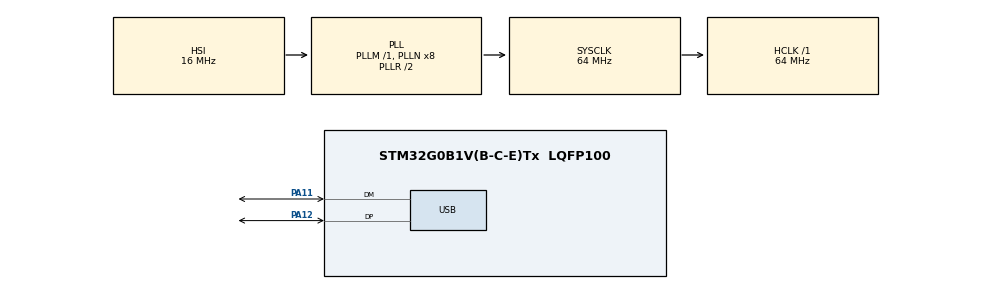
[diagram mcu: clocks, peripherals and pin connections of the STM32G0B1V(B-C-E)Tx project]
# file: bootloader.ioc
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Mcu.Family=STM32G0
Mcu.Name=STM32G0B1V(B-C-E)Tx
Mcu.Package=LQFP100
NVIC.USB_UCPD1_2_IRQn=true\:1\:0\:false\:false\:true\:true\:true\:true
PA11\ [PA9].Mode=Device
PA11\ [PA9].Signal=USB_DM
PA12\ [PA10].Mode=Device
PA12\ [PA10].Signal=USB_DP
ProjectManager.HeapSize=0x200
ProjectManager.StackSize=0x400
ProjectManager.TargetToolchain=CMake
RCC.ADCFreq_Value=64000000
RCC.AHBFreq_Value=64000000
RCC.CortexFreq_Value=64000000
RCC.EXTERNAL_CLOCK_VALUE=48000
RCC.HCLKFreq_Value=64000000
RCC.HSE_VALUE=8000000
RCC.HSI48_VALUE=48000000
RCC.HSI_VALUE=16000000
RCC.LSE_VALUE=32768
RCC.PREFETCH_ENABLE=0
RCC.SYSCLKFreq_VALUE=64000000
RCC.SYSCLKSource=RCC_SYSCLKSOURCE_PLLCLK
RCC.USBFreq_Value=48000000
RCC.VCOOutputFreq_Value=128000000
USB_DEVICE.CLASS_NAME_FS=DFU
USB_DEVICE.VirtualMode=Dfu
USB_DEVICE.VirtualModeFS=Dfu_FS
VP_RCC_USB.Mode=CRS SYNC Source USB
VP_USB_DEVICE_VS_USB_DEVICE_DFU_FS.Mode=DFU_FS
board=custom

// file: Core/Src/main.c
/* USER CODE BEGIN Header */
/**
  ******************************************************************************
  * @file           : main.c
  * @brief          : Main program body
  ******************************************************************************
  * @attention
  *
  * Copyright (c) 2026 STMicroelectronics.
  * All rights reserved.
  *
  * This software is licensed under terms that can be found in the LICENSE file
  * in the root directory of this software component.
  * If no LICENSE file comes with this software, it is provided AS-IS.
  *
  ******************************************************************************
  */
/* USER CODE END Header */
#include "main.h"
#include "usb_device.h"

/* USER CODE BEGIN Includes */
#include "bootloader.h"
#include "app_openbootloader.h"
#include "timeout.h"
#include "usb_hub.h"
#include "ws2812.h"
/* USER CODE END Includes */

void SystemClock_Config(void);
static void MX_GPIO_Init(void);

int main(void)
{

  /* USER CODE BEGIN 1 */
  /* ES0548 2.2.10: cross-bank execution requires flash prefetch disabled. */
  __HAL_FLASH_PREFETCH_BUFFER_DISABLE();
  /* USER CODE END 1 */

  /* MCU Configuration--------------------------------------------------------*/

  /* Reset of all peripherals, Initializes the Flash interface and the Systick. */
  HAL_Init();

  /* Configure the system clock */
  SystemClock_Config();

  /* USER CODE BEGIN SysInit */
  ws2812_init();
  ws2812_set_rgb(0U, 0U, 0U, 32U);
  OpenBootloader_Init();
  bootloader_is_enabled();
  timeout_timer_init();
  usb_hub_init();
  /* USER CODE END SysInit */

  /* Initialize all configured peripherals */
  MX_GPIO_Init();
  MX_USB_Device_Init();

  /* Infinite loop */
  while (1)
  {

    /* USER CODE BEGIN 3 */
    OpenBootloader_ProtocolDetection();
    bootloader_process();
  }
  /* USER CODE END 3 */
}

void SystemClock_Config(void)
{
  RCC_OscInitTypeDef RCC_OscInitStruct = {0};
  RCC_ClkInitTypeDef RCC_ClkInitStruct = {0};
  RCC_CRSInitTypeDef pInit = {0};

  /** Configure the main internal regulator output voltage
  */
  HAL_PWREx_ControlVoltageScaling(PWR_REGULATOR_VOLTAGE_SCALE1);

  /** Initializes the RCC Oscillators according to the specified parameters
  * in the RCC_OscInitTypeDef structure.
  */
  RCC_OscInitStruct.OscillatorType = RCC_OSCILLATORTYPE_HSI|RCC_OSCILLATORTYPE_HSI48;
  RCC_OscInitStruct.HSIState = RCC_HSI_ON;
  RCC_OscInitStruct.HSI48State = RCC_HSI48_ON;
  RCC_OscInitStruct.HSIDiv = RCC_HSI_DIV1;
  RCC_OscInitStruct.HSICalibrationValue = RCC_HSICALIBRATION_DEFAULT;
  RCC_OscInitStruct.PLL.PLLState = RCC_PLL_ON;
  RCC_OscInitStruct.PLL.PLLSource = RCC_PLLSOURCE_HSI;
  RCC_OscInitStruct.PLL.PLLM = RCC_PLLM_DIV1;
  RCC_OscInitStruct.PLL.PLLN = 8;
  RCC_OscInitStruct.PLL.PLLP = RCC_PLLP_DIV2;
  RCC_OscInitStruct.PLL.PLLQ = RCC_PLLQ_DIV2;
  RCC_OscInitStruct.PLL.PLLR = RCC_PLLR_DIV2;
  if (HAL_RCC_OscConfig(&RCC_OscInitStruct) != HAL_OK)
  {
    Error_Handler();
  }

  /** Initializes the CPU, AHB and APB buses clocks
  */
  RCC_ClkInitStruct.ClockType = RCC_CLOCKTYPE_HCLK|RCC_CLOCKTYPE_SYSCLK
                              |RCC_CLOCKTYPE_PCLK1;
  RCC_ClkInitStruct.SYSCLKSource = RCC_SYSCLKSOURCE_PLLCLK;
  RCC_ClkInitStruct.AHBCLKDivider = RCC_SYSCLK_DIV1;
  RCC_ClkInitStruct.APB1CLKDivider = RCC_HCLK_DIV1;

  if (HAL_RCC_ClockConfig(&RCC_ClkInitStruct, FLASH_LATENCY_2) != HAL_OK)
  {
    Error_Handler();
  }

  /** Enable the SYSCFG APB clock
  */
  __HAL_RCC_CRS_CLK_ENABLE();

  /** Configures CRS
  */
  pInit.Prescaler = RCC_CRS_SYNC_DIV1;
  pInit.Source = RCC_CRS_SYNC_SOURCE_USB;
  pInit.Polarity = RCC_CRS_SYNC_POLARITY_RISING;
  pInit.ReloadValue = __HAL_RCC_CRS_RELOADVALUE_CALCULATE(48000000,1000);
  pInit.ErrorLimitValue = 34;
  pInit.HSI48CalibrationValue = 32;

  HAL_RCCEx_CRSConfig(&pInit);
}

static void MX_GPIO_Init(void)
{

  /* GPIO Ports Clock Enable */
  __HAL_RCC_GPIOA_CLK_ENABLE();

}

void Error_Handler(void)
{
  __disable_irq();
  while (1)
  {
  }
}
